# STM32L162 register map
File version: 1.5
CPU: CM3 r1p1, little endian, no MPU, no FPU, 4 interrupt priority bits
Registers are 32-bit, read-write, reset 0x0 unless marked. A register's access mark holds for its fields unless they carry their own. Offsets are from the block's base; [hi:lo] are bit positions; {n}, {i} and the like mark numbered series.

## SYSCFG — System configuration controller
Base 0x40010000
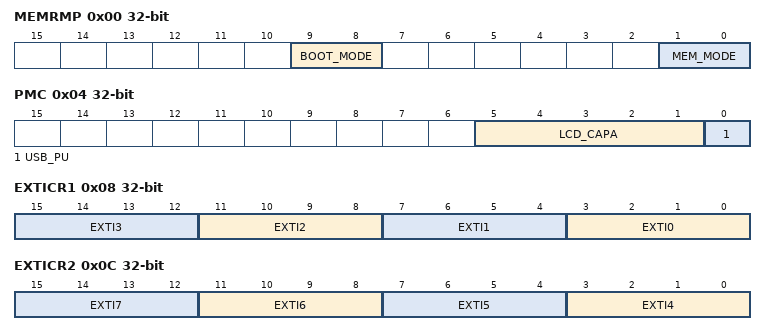
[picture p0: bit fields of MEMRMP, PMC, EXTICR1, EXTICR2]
0x00 MEMRMP access per field — memory remap register
  [9:8] BOOT_MODE ro, [1:0] MEM_MODE rw
0x04 PMC — peripheral mode configuration register
  [5:1] LCD_CAPA — decoupling capacitance connection
  [0] USB_PU — USB pull-up
0x08 EXTICR1 — external interrupt configuration register 1
  [4n+3:4n] EXTI{n} (n=0..3) — EXTI x configuration (x = 0 to 3)
0x0C EXTICR2 — external interrupt configuration register 2
  [4n-13:4n-16] EXTI{n} (n=4..7) — EXTI x configuration (x = 4 to 7)
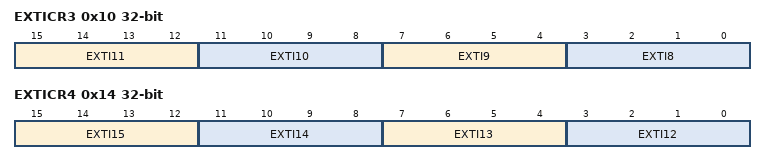
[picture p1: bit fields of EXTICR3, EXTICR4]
0x10 EXTICR3 — external interrupt configuration register 3
  [15:12] EXTI11 — EXTI x configuration (x = 8 to 11)
  [11:8] EXTI10
  [7:4] EXTI9 — EXTI x configuration (x = 8 to 11)
  [3:0] EXTI8 — EXTI x configuration (x = 8 to 11)
0x14 EXTICR4 — external interrupt configuration register 4
  [15:12] EXTI15 — EXTI x configuration (x = 12 to 15)
  [11:8] EXTI14
  [7:4] EXTI13
  [3:0] EXTI12

## TIM6 — Basic timers
Base 0x40001000
Same registers: TIM7 0x40001400
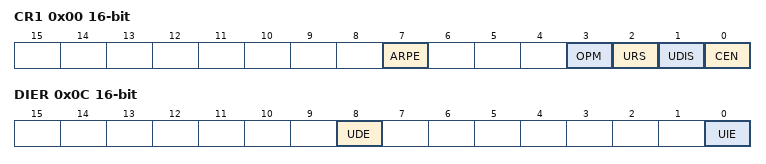
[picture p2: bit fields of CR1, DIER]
0x00 CR1 16-bit — TIM6 control register 1
  [7] ARPE — Auto-reload preload enable
    0=Disabled (TIMx_APRR register is not buffered); 1=Enabled (TIMx_APRR register is buffered)
  [3] OPM — One-pulse mode
    0=Disabled (Counter is not stopped at update event); 1=Enabled (Counter stops counting at the next update event (clearing the CEN bit))
  [2] URS — Update request source
    0=AnyEvent (Any of counter overflow/underflow, setting UG, or update through slave mode, generates an update interrupt or DMA request); 1=CounterOnly (Only counter overflow/underflow generates an update interrupt or DMA request)
  [1] UDIS — Update disable
    0=Enabled (Update event enabled); 1=Disabled (Update event disabled)
  [0] CEN — Counter enable
    0=Disabled (Counter disabled); 1=Enabled (Counter enabled)
0x04 CR2 16-bit — TIM6 control register 2
  [6:4] MMS — Master mode selection
    0=Reset (Use UG bit from TIMx_EGR register); 1=Enable (Use CNT bit from TIMx_CEN register); 2=Update (Use the update event)
0x0C DIER 16-bit — TIM6 DMA/Interrupt enable register
  [8] UDE — Update DMA request enable
    0=Disabled (Update DMA request disabled); 1=Enabled (Update DMA request enabled)
  [0] UIE — Update interrupt enable
    0=Disabled (Update interrupt disabled); 1=Enabled (Update interrupt enabled)
0x10 SR 16-bit — TIM6 status register
  [0] UIF write-0-clears — Update interrupt flag
    on read: 0=NoUpdateOccurred; 1=UpdatePending (Update interrupt pending) | on write: 0=Clear flag
0x14 EGR 16-bit wo — TIM6 event generation register
  [0] UG — Update generation
    1=Update (Re-initializes the timer counter and generates an update of the registers.)
0x24 CNT 16-bit — TIM6 counter
0x28 PSC 16-bit — TIM6 prescaler
  [15:0] PSC — Prescaler valueThe counter clock frequency CK_CNT is equal to fCK_PSC / (PSC[15:0] + 1).
0x2C ARR 16-bit reset 0xFFFF — TIM6 auto-reload register
  [15:0] ARR — Prescaler value

## WWDG — Window watchdog
Base 0x40002C00
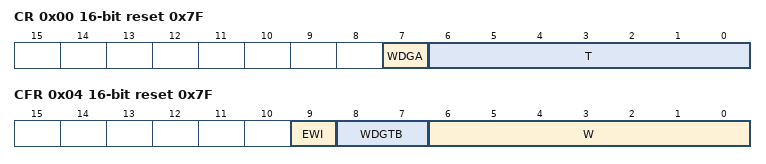
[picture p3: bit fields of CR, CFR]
0x00 CR 16-bit access per field reset 0x7F — Control register
  [7] WDGA wo — Activation bit
    0=Disabled (Watchdog disabled); 1=Enabled (Watchdog enabled)
  [6:0] T rw — 7-bit counter (MSB to LSB)
0x04 CFR 16-bit access not given reset 0x7F — Configuration register
  [9] EWI wo — Early wakeup interrupt
    1=Enable (interrupt occurs whenever the counter reaches the value 0x40)
  [8:7] WDGTB — Timer base
    0=Div1 (Counter clock (PCLK1 div 4096) div 1); 1=Div2 (Counter clock (PCLK1 div 4096) div 2); 2=Div4 (Counter clock (PCLK1 div 4096) div 4); 3=Div8 (Counter clock (PCLK1 div 4096) div 8)
  [6:0] W rw — 7-bit window value
0x08 SR 16-bit
  [0] EWIF write-0-clears
    on read: 0=Finished (The EWI Interrupt Service Routine has been serviced); 1=Pending (The EWI Interrupt Service Routine has been triggered) | on write: 0=Finished (The EWI Interrupt Service Routine has been serviced)

## DBGMCU — debug support
Base 0xE0042000
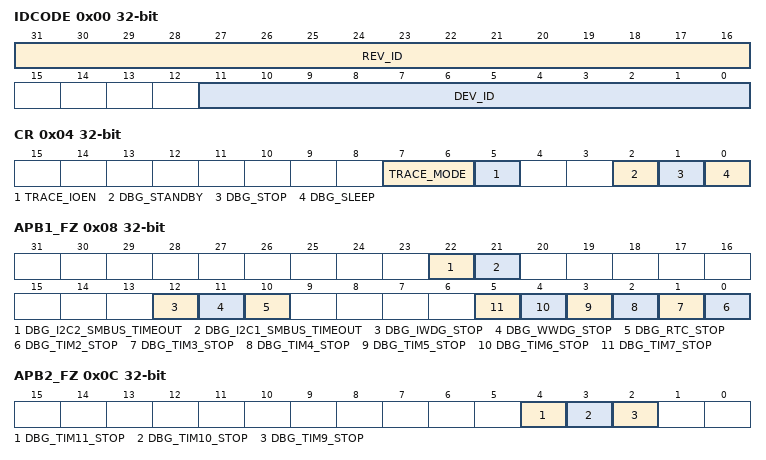
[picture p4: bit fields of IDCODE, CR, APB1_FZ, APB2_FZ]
0x00 IDCODE ro — DBGMCU_IDCODE
  [31:16] REV_ID — Revision identifie
  [11:0] DEV_ID — Device identifier
0x04 CR — Debug MCU configuration register
  [7:6] TRACE_MODE — Trace pin assignment control
  [5] TRACE_IOEN — Trace pin assignment control
  [2] DBG_STANDBY — Debug Standby mode
  [1] DBG_STOP — Debug Stop mode
  [0] DBG_SLEEP — Debug Sleep mode
0x08 APB1_FZ — Debug MCU APB1 freeze register1
  [22] DBG_I2C2_SMBUS_TIMEOUT — SMBUS timeout mode stopped when core is halted
  [21] DBG_I2C1_SMBUS_TIMEOUT — SMBUS timeout mode stopped when core is halted
  [12] DBG_IWDG_STOP — Debug independent watchdog stopped when core is halted
  [11] DBG_WWDG_STOP — Debug window watchdog stopped when core is halted
  [10] DBG_RTC_STOP — Debug RTC stopped when core is halted
  [n-2] DBG_TIM{n}_STOP (n=2..7) — TIM{n} counter stopped when core is halted
0x0C APB2_FZ — Debug MCU APB1 freeze register 2
  [4] DBG_TIM11_STOP — TIM counter stopped when core is halted
  [3] DBG_TIM10_STOP — TIM counter stopped when core is halted
  [2] DBG_TIM9_STOP — TIM counter stopped when core is halted
